AUTOSAR XML (schema 4-3-0)
package /DBCImport/CANTP
  can tp config CanTpConfig_Project: communication-cluster=Project, can-tp-ecu=ECU1
    4 x can tp channel, all with channel-mode=HALF-DUPLEX-MODE:
      CanTpChannel{0..3}: channel-id={0..3}
    tp-connections:
      addressing-format=STANDARD, can-tp-channel=CanTpChannel1, data-pdu=NPdu_Project_GST_Msg_TP2, flow-control-pdu=NPdu_Project_ECU1_Msg_TP2, max-block-size=0, padding-activation=true, ta-type=PHYSICAL, tp-sdu=ISignalIPdu_Project_GST_Msg_TP2
      addressing-format=STANDARD, can-tp-channel=CanTpChannel0, data-pdu=NPdu_Project_GST_Msg_TP1, flow-control-pdu=NPdu_Project_ECU1_Msg_TP1, max-block-size=0, padding-activation=true, ta-type=PHYSICAL, tp-sdu=ISignalIPdu_Project_GST_Msg_TP1
      addressing-format=STANDARD, can-tp-channel=CanTpChannel2, data-pdu=NPdu_Project_ECU1_GST_Msg_TP, flow-control-pdu=NPdu_Project_GST_Msg_TP_Phys, max-block-size=0, padding-activation=true, ta-type=PHYSICAL, tp-sdu=DcmIPdu_Project_ECU1_GST_Msg_TP
      addressing-format=STANDARD, can-tp-channel=CanTpChannel2, data-pdu=NPdu_Project_GST_Msg_TP_Phys, flow-control-pdu=NPdu_Project_ECU1_GST_Msg_TP, max-block-size=0, padding-activation=true, ta-type=PHYSICAL, tp-sdu=DcmIPdu_Project_GST_Msg_TP_Phys
      addressing-format=STANDARD, can-tp-channel=CanTpChannel1, data-pdu=NPdu_Project_ECU1_Msg_TP2, flow-control-pdu=NPdu_Project_GST_Msg_TP2, max-block-size=0, padding-activation=true, ta-type=PHYSICAL, tp-sdu=ISignalIPdu_Project_ECU1_Msg_TP2
      addressing-format=STANDARD, can-tp-channel=CanTpChannel3, data-pdu=NPdu_Project_GST_Msg_TP_Func, max-block-size=0, padding-activation=true, ta-type=FUNCTIONAL, tp-sdu=DcmIPdu_Project_GST_Msg_TP_Func
      addressing-format=STANDARD, can-tp-channel=CanTpChannel0, data-pdu=NPdu_Project_ECU1_Msg_TP1, flow-control-pdu=NPdu_Project_GST_Msg_TP1, max-block-size=0, padding-activation=true, ta-type=PHYSICAL, tp-sdu=ISignalIPdu_Project_ECU1_Msg_TP1
    can tp node ECU1: connector=Conn_ECU1_Project
package /DBCImport/SWCComposition
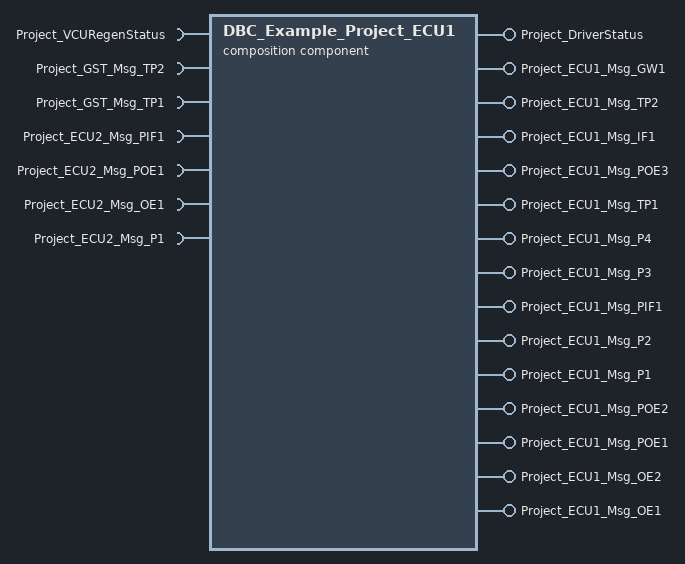
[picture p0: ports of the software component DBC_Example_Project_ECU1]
  composition sw component type DBC_Example_Project_ECU1
    15 x provide port:
      Project_DriverStatus: provided-interface=Project_DriverStatus
      Project_ECU1_Msg_GW1: provided-interface=Project_ECU1_Msg_GW1
      Project_ECU1_Msg_TP2: provided-interface=Project_ECU1_Msg_TP2
      Project_ECU1_Msg_IF1: provided-interface=Project_ECU1_Msg_IF1
      Project_ECU1_Msg_POE3: provided-interface=Project_ECU1_Msg_POE3
      Project_ECU1_Msg_TP1: provided-interface=Project_ECU1_Msg_TP1
      Project_ECU1_Msg_P4: provided-interface=Project_ECU1_Msg_P4
      Project_ECU1_Msg_P3: provided-interface=Project_ECU1_Msg_P3
      Project_ECU1_Msg_PIF1: provided-interface=Project_ECU1_Msg_PIF1
      Project_ECU1_Msg_P2: provided-interface=Project_ECU1_Msg_P2
      Project_ECU1_Msg_P1: provided-interface=Project_ECU1_Msg_P1
      Project_ECU1_Msg_POE2: provided-interface=Project_ECU1_Msg_POE2
      Project_ECU1_Msg_POE1: provided-interface=Project_ECU1_Msg_POE1
      Project_ECU1_Msg_OE2: provided-interface=Project_ECU1_Msg_OE2
      Project_ECU1_Msg_OE1: provided-interface=Project_ECU1_Msg_OE1
    7 x require port:
      Project_VCURegenStatus: required-interface=Project_VCURegenStatus
      Project_GST_Msg_TP2: required-interface=Project_GST_Msg_TP2
      Project_GST_Msg_TP1: required-interface=Project_GST_Msg_TP1
      Project_ECU2_Msg_PIF1: required-interface=Project_ECU2_Msg_PIF1
      Project_ECU2_Msg_POE1: required-interface=Project_ECU2_Msg_POE1
      Project_ECU2_Msg_OE1: required-interface=Project_ECU2_Msg_OE1
      Project_ECU2_Msg_P1: required-interface=Project_ECU2_Msg_P1
package /DBCImport/CLUSTERS
  can cluster Project: baudrate=500000, protocol-name=CAN, speed=500
    can physical channel Project: comm-connectors=Conn_ECU1_Project
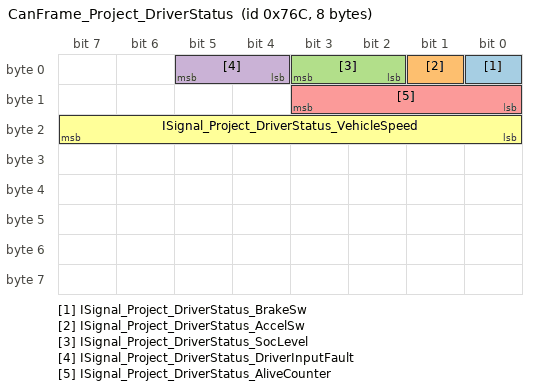
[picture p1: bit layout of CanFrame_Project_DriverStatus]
      frame CanFrame_Project_DriverStatus: id 0x76C, frame-length=8, can-addressing-mode=STANDARD, can-fd-frame-support=false
        pdu ISignalIPdu_Project_DriverStatus: length=8, minimum-delay=0.0, transmission-mode-true-timing=cyclic-timing={time-offset=0.0, time-period=0.01}
          signal ISignal_Project_DriverStatus_BrakeSw: start 0, 1 bit, little-endian, init-value=0, base-type=boolean, compu {0=OFF, 1=ON, phys=raw for raw 0..1}, transfer-property=PENDING
          signal ISignal_Project_DriverStatus_AccelSw: start 1, 1 bit, little-endian, init-value=0, base-type=boolean, compu {0=OFF, 1=ON, phys=raw for raw 0..1}, transfer-property=PENDING
          signal ISignal_Project_DriverStatus_SocLevel: start 2, 2 bit, little-endian, init-value=0, base-type=uint8, compu {0=LOW, 1=MID, 2=HIGH, 3=FULL, phys=raw for raw 0..3}, transfer-property=PENDING
          signal ISignal_Project_DriverStatus_DriverInputFault: start 4, 2 bit, little-endian, init-value=0, base-type=uint8, compu-method=ISignal_Project_DriverStatus_DriverInputFault, transfer-property=PENDING
          signal ISignal_Project_DriverStatus_AliveCounter: start 8, 4 bit, little-endian, init-value=0, base-type=uint8, compu {phys=raw for raw 0..15}, transfer-property=PENDING
          signal ISignal_Project_DriverStatus_VehicleSpeed: start 16, 8 bit, little-endian, init-value=0, base-type=uint8, compu {phys=raw for raw 0..255; unit km/h}, unit=km/h, transfer-property=PENDING
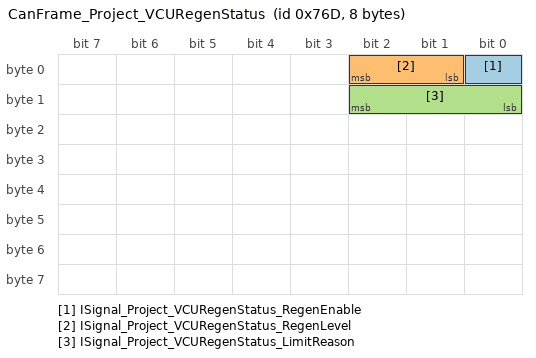
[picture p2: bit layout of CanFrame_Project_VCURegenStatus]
      frame CanFrame_Project_VCURegenStatus: id 0x76D, frame-length=8, can-addressing-mode=STANDARD, can-fd-frame-support=false
        pdu ISignalIPdu_Project_VCURegenStatus: length=8, minimum-delay=0.0, transmission-mode-true-timing=cyclic-timing={time-offset=0.0, time-period=0.01}
          signal ISignal_Project_VCURegenStatus_RegenEnable: start 0, 1 bit, little-endian, init-value=0, base-type=boolean, compu {0=DISABLE, 1=ENABLE, phys=raw for raw 0..1}, transfer-property=PENDING
          signal ISignal_Project_VCURegenStatus_RegenLevel: start 1, 2 bit, little-endian, init-value=0, base-type=uint8, compu {0=NONE, 1=LOW, 2=MID, 3=HIGH, phys=raw for raw 0..3}, transfer-property=PENDING
          signal ISignal_Project_VCURegenStatus_LimitReason: start 8, 3 bit, little-endian, init-value=0, base-type=uint8, compu-method=ISignal_Project_VCURegenStatus_LimitReason, transfer-property=PENDING
      frame CanFrame_Project_GST_Msg_TP2: id 0x707, frame-length=8, can-addressing-mode=STANDARD, can-fd-frame-support=false
        pdu ISignalIPdu_Project_GST_Msg_TP2: length=8, minimum-delay=0.0, transmission-mode-true-timing=event-controlled-timing={number-of-repetitions=0, repetition-period=0.0}
          signal ISignal_Project_GST_Msg_TP2_Project_GST_Msg_TP2_signal: start 0, 64 bit, opaque, init-value=8 x 0, compu {phys=raw for raw 0}, implementation-data-type=array8uint8, transfer-property=TRIGGERED-WITHOUT-REPETITION
        n pdu NPdu_Project_GST_Msg_TP2: length=8, meta-data-length=0
      frame CanFrame_Project_GST_Msg_TP1: id 0x706, frame-length=8, can-addressing-mode=STANDARD, can-fd-frame-support=false
        pdu ISignalIPdu_Project_GST_Msg_TP1: length=8, minimum-delay=0.0, transmission-mode-true-timing=event-controlled-timing={number-of-repetitions=0, repetition-period=0.0}
          signal ISignal_Project_GST_Msg_TP1_Project_GST_Msg_TP1_signal: start 0, 64 bit, opaque, init-value=8 x 0, compu {phys=raw for raw 0}, implementation-data-type=array8uint8, transfer-property=TRIGGERED-WITHOUT-REPETITION
        n pdu NPdu_Project_GST_Msg_TP1: length=8, meta-data-length=0
      frame CanFrame_Project_ECU1_GST_Msg_TP: id 0x705, frame-length=8, can-addressing-mode=STANDARD, can-fd-frame-support=false
        dcm i pdu DcmIPdu_Project_ECU1_GST_Msg_TP: length=8
        n pdu NPdu_Project_ECU1_GST_Msg_TP: length=8, meta-data-length=0
      frame CanFrame_Project_ECU1_Msg_GW1: id 0x55, frame-length=8, can-addressing-mode=STANDARD, can-fd-frame-support=false
        pdu ISignalIPdu_Project_ECU1_Msg_GW1: length=8, minimum-delay=0.02, transmission-mode-true-timing=event-controlled-timing={number-of-repetitions=3, repetition-period=0.04}
          signal ISignal_Project_ECU1_Msg_GW1_ECU1_Msg_GW1_Sig1: start 7, 8 bit, big-endian, init-value=0, base-type=uint8, compu {phys=raw for raw 0}, transfer-property=TRIGGERED
          signal ISignal_Project_ECU1_Msg_GW1_ECU1_Msg_GW1_Sig2: start 15, 8 bit, big-endian, init-value=0, base-type=uint8, compu {phys=raw for raw 0}, transfer-property=TRIGGERED
      frame CanFrame_Project_GST_Msg_TP_Phys: id 0x703, frame-length=8, can-addressing-mode=STANDARD, can-fd-frame-support=false
        dcm i pdu DcmIPdu_Project_GST_Msg_TP_Phys: length=8
        n pdu NPdu_Project_GST_Msg_TP_Phys: length=8, meta-data-length=0
      frame CanFrame_Project_ECU1_Msg_TP2: id 0x704, frame-length=8, can-addressing-mode=STANDARD, can-fd-frame-support=false
        pdu ISignalIPdu_Project_ECU1_Msg_TP2: length=8, minimum-delay=0.0, transmission-mode-true-timing=event-controlled-timing={number-of-repetitions=0, repetition-period=0.0}
          signal ISignal_Project_ECU1_Msg_TP2_Project_ECU1_Msg_TP2_signal: start 0, 64 bit, opaque, init-value=8 x 0, compu {phys=raw for raw 0}, implementation-data-type=array8uint8, transfer-property=TRIGGERED-WITHOUT-REPETITION
        n pdu NPdu_Project_ECU1_Msg_TP2: length=8, meta-data-length=0
      frame CanFrame_Project_ECU2_Msg_PIF1: id 0x301, frame-length=8, can-addressing-mode=STANDARD, can-fd-frame-support=false
        pdu ISignalIPdu_Project_ECU2_Msg_PIF1: length=8, minimum-delay=0.02, transmission-mode-true-timing={cyclic-timing={time-offset=0.0, time-period=0.5}, event-controlled-timing={number-of-repetitions=3, repetition-period=0.2}}
          signal ISignal_Project_ECU2_Msg_PIF1_ECU2_Msg_PIF1_Sig1: start 23, 8 bit, big-endian, init-value=0, base-type=uint8, compu {phys=raw for raw 0}, transfer-property=TRIGGERED
          signal ISignal_Project_ECU2_Msg_PIF1_ECU2_Msg_PIF1_Sig2: start 31, 8 bit, big-endian, init-value=0, base-type=uint8, compu {phys=raw for raw 0}, transfer-property=TRIGGERED
      frame CanFrame_Project_ECU2_Msg_POE1: id 0x103, frame-length=8, can-addressing-mode=STANDARD, can-fd-frame-support=false
        pdu ISignalIPdu_Project_ECU2_Msg_POE1: length=8, minimum-delay=0.02, transmission-mode-true-timing={cyclic-timing={time-offset=0.0, time-period=0.5}, event-controlled-timing={number-of-repetitions=3, repetition-period=0.04}}
          signal ISignal_Project_ECU2_Msg_POE1_ECU2_Msg_POE1_Sig2: start 23, 8 bit, big-endian, init-value=0, base-type=uint8, compu {phys=raw for raw 0}, transfer-property=TRIGGERED-ON-CHANGE
          signal ISignal_Project_ECU2_Msg_POE1_ECU2_Msg_POE1_Sig1: start 31, 8 bit, big-endian, init-value=0, base-type=uint8, compu {phys=raw for raw 0}, transfer-property=TRIGGERED
      frame CanFrame_Project_ECU1_Msg_IF1: id 0x200, frame-length=8, can-addressing-mode=STANDARD, can-fd-frame-support=false
        pdu ISignalIPdu_Project_ECU1_Msg_IF1: length=8, minimum-delay=0.02, transmission-mode-true-timing=event-controlled-timing={number-of-repetitions=3, repetition-period=0.2}
          signal ISignal_Project_ECU1_Msg_IF1_ECU1_Msg_IF1_Sig1: start 7, 8 bit, big-endian, init-value=0, base-type=uint8, compu {phys=raw for raw 0}, transfer-property=TRIGGERED
          signal ISignal_Project_ECU1_Msg_IF1_ECU1_Msg_IF1_Sig2: start 15, 8 bit, big-endian, init-value=0, base-type=uint8, compu {phys=raw for raw 0}, transfer-property=TRIGGERED
      frame CanFrame_Project_ECU2_Msg_OE1: id 0x3, frame-length=8, can-addressing-mode=STANDARD, can-fd-frame-support=false
        pdu ISignalIPdu_Project_ECU2_Msg_OE1: length=8, minimum-delay=0.02, transmission-mode-true-timing=event-controlled-timing={number-of-repetitions=3, repetition-period=0.04}
          signal ISignal_Project_ECU2_Msg_OE1_ECU2_Msg_OE1_Sig1: start 7, 8 bit, big-endian, init-value=0, base-type=uint8, compu {phys=raw for raw 0}, transfer-property=TRIGGERED-WITHOUT-REPETITION
          signal ISignal_Project_ECU2_Msg_OE1_ECU2_Msg_OE1_Sig2: start 15, 8 bit, big-endian, init-value=0, base-type=uint8, compu {phys=raw for raw 0}, transfer-property=TRIGGERED-WITHOUT-REPETITION
      frame CanFrame_Project_ECU2_Msg_P1: id 0x503, frame-length=2, can-addressing-mode=STANDARD, can-fd-frame-support=false
        pdu ISignalIPdu_Project_ECU2_Msg_P1: length=2, minimum-delay=0.02, transmission-mode-true-timing=cyclic-timing={time-offset=0.0, time-period=0.5}
          signal ISignal_Project_ECU2_Msg_P1_ECU2_Msg_P1_Sig1: start 7, 8 bit, big-endian, init-value=0, base-type=uint8, compu {phys=raw for raw 0}, transfer-property=PENDING
          signal ISignal_Project_ECU2_Msg_P1_ECU2_Msg_P1_Sig2: start 15, 8 bit, big-endian, init-value=0, base-type=uint8, compu {phys=raw for raw 0}, transfer-property=PENDING
      frame CanFrame_Project_ECU1_Msg_POE3: id 0x100, frame-length=8, can-addressing-mode=STANDARD, can-fd-frame-support=false
        pdu ISignalIPdu_Project_ECU1_Msg_POE3: length=8, minimum-delay=0.02, transmission-mode-true-timing={cyclic-timing={time-offset=0.0, time-period=0.2}, event-controlled-timing={number-of-repetitions=3, repetition-period=0.04}}
          signal ISignal_Project_ECU1_Msg_POE3_ECU1_Msg_POE3_Sig1: start 7, 8 bit, big-endian, init-value=0, base-type=uint8, compu {phys=raw for raw 0..255}, transfer-property=TRIGGERED-WITHOUT-REPETITION
          signal ISignal_Project_ECU1_Msg_POE3_ECU1_Msg_POE3_Sig2: start 15, 8 bit, big-endian, init-value=0, base-type=uint8, compu {phys=raw for raw 0}, transfer-property=TRIGGERED-ON-CHANGE-WITHOUT-REPETITION
      frame CanFrame_Project_GST_Msg_TP_Func: id 0x7DF, frame-length=8, can-addressing-mode=STANDARD, can-fd-frame-support=false
        dcm i pdu DcmIPdu_Project_GST_Msg_TP_Func: length=8
        n pdu NPdu_Project_GST_Msg_TP_Func: length=8, meta-data-length=0
      frame CanFrame_Project_ECU1_Msg_TP1: id 0x701, frame-length=8, can-addressing-mode=STANDARD, can-fd-frame-support=false
        pdu ISignalIPdu_Project_ECU1_Msg_TP1: length=8, minimum-delay=0.0, transmission-mode-true-timing=event-controlled-timing={number-of-repetitions=0, repetition-period=0.0}
          signal ISignal_Project_ECU1_Msg_TP1_Project_ECU1_Msg_TP1_signal: start 0, 64 bit, opaque, init-value=8 x 0, compu {phys=raw for raw 0}, implementation-data-type=array8uint8, transfer-property=TRIGGERED-WITHOUT-REPETITION
        n pdu NPdu_Project_ECU1_Msg_TP1: length=8, meta-data-length=0
      frame CanFrame_Project_ECU1_Msg_P4: id 0x602, frame-length=8, can-addressing-mode=STANDARD, can-fd-frame-support=false
        pdu ISignalIPdu_Project_ECU1_Msg_P4: length=8, minimum-delay=0.02, transmission-mode-true-timing=cyclic-timing={time-offset=0.0, time-period=0.2}
          signal ISignal_Project_ECU1_Msg_P4_ECU1_Msg_P4_Sig1: start 7, 8 bit, big-endian, init-value=0, base-type=uint8, compu {phys=raw for raw 0}, transfer-property=PENDING
          signal ISignal_Project_ECU1_Msg_P4_ECU1_Msg_P4_Sig2: start 15, 8 bit, big-endian, init-value=0, base-type=uint8, compu {phys=raw for raw 0}, transfer-property=PENDING
      frame CanFrame_Project_ECU1_Msg_P3: id 0x601, frame-length=8, can-addressing-mode=STANDARD, can-fd-frame-support=false
        pdu ISignalIPdu_Project_ECU1_Msg_P3: length=8, minimum-delay=0.02, transmission-mode-true-timing=cyclic-timing={time-offset=0.0, time-period=0.2}
          signal ISignal_Project_ECU1_Msg_P3_ECU1_Msg_P3_Sig1: start 7, 8 bit, big-endian, init-value=0, base-type=uint8, compu {phys=raw for raw 0}, transfer-property=PENDING
          signal ISignal_Project_ECU1_Msg_P3_ECU1_Msg_P3_Sig2: start 15, 8 bit, big-endian, init-value=0, base-type=uint8, compu {phys=raw for raw 0}, transfer-property=PENDING
      frame CanFrame_Project_ECU1_Msg_PIF1: id 0x300, frame-length=8, can-addressing-mode=STANDARD, can-fd-frame-support=false
        pdu ISignalIPdu_Project_ECU1_Msg_PIF1: length=8, minimum-delay=0.02, transmission-mode-true-timing={cyclic-timing={time-offset=0.0, time-period=0.5}, event-controlled-timing={number-of-repetitions=3, repetition-period=0.2}}
          signal ISignal_Project_ECU1_Msg_PIF1_ECU1_Msg_PIF1_Sig1: start 7, 8 bit, big-endian, init-value=0, base-type=uint8, compu {phys=raw for raw 0}, transfer-property=TRIGGERED
          signal ISignal_Project_ECU1_Msg_PIF1_ECU1_Msg_PIF1_Sig2: start 15, 8 bit, big-endian, init-value=0, base-type=uint8, compu {phys=raw for raw 0}, transfer-property=TRIGGERED
      frame CanFrame_Project_ECU1_Msg_P2: id 0x502, frame-length=8, can-addressing-mode=STANDARD, can-fd-frame-support=false
        pdu ISignalIPdu_Project_ECU1_Msg_P2: length=8, minimum-delay=0.02, transmission-mode-true-timing=cyclic-timing={time-offset=0.0, time-period=0.2}
          signal ISignal_Project_ECU1_Msg_P2_ECU1_Msg_P2_Sig1: start 7, 8 bit, big-endian, init-value=0, base-type=uint8, compu {phys=raw for raw 0}, transfer-property=PENDING
          signal ISignal_Project_ECU1_Msg_P2_ECU1_Msg_P2_Sig2: start 15, 8 bit, big-endian, init-value=0, base-type=uint8, compu {phys=raw for raw 0}, transfer-property=PENDING
      frame CanFrame_Project_ECU1_Msg_P1: id 0x501, frame-length=8, can-addressing-mode=STANDARD, can-fd-frame-support=false
        pdu ISignalIPdu_Project_ECU1_Msg_P1: length=8, minimum-delay=0.02, transmission-mode-true-timing=cyclic-timing={time-offset=0.0, time-period=0.5}
          signal ISignal_Project_ECU1_Msg_P1_ECU1_Msg_P1_Sig1: start 7, 8 bit, big-endian, init-value=0, base-type=uint8, compu {phys=raw for raw 0}, transfer-property=PENDING
          signal ISignal_Project_ECU1_Msg_P1_ECU1_Msg_P1_Sig2: start 15, 8 bit, big-endian, init-value=0, base-type=uint8, compu {phys=raw for raw 0}, transfer-property=PENDING
      frame CanFrame_Project_ECU1_Msg_POE2: id 0x102, frame-length=8, can-addressing-mode=STANDARD, can-fd-frame-support=false
        pdu ISignalIPdu_Project_ECU1_Msg_POE2: length=8, minimum-delay=0.02, transmission-mode-true-timing={cyclic-timing={time-offset=0.0, time-period=0.2}, event-controlled-timing={number-of-repetitions=3, repetition-period=0.04}}
          signal ISignal_Project_ECU1_Msg_POE2_ECU1_Msg_POE2_Sig1: start 7, 8 bit, big-endian, init-value=0, base-type=uint8, compu {phys=raw for raw 0}, transfer-property=TRIGGERED
          signal ISignal_Project_ECU1_Msg_POE2_ECU1_Msg_POE2_Sig2: start 15, 8 bit, big-endian, init-value=0, base-type=uint8, compu {phys=raw for raw 0}, transfer-property=TRIGGERED-ON-CHANGE
      frame CanFrame_Project_ECU1_Msg_POE1: id 0x101, frame-length=8, can-addressing-mode=STANDARD, can-fd-frame-support=false
        pdu ISignalIPdu_Project_ECU1_Msg_POE1: length=8, minimum-delay=0.02, transmission-mode-true-timing={cyclic-timing={time-offset=0.0, time-period=0.2}, event-controlled-timing={number-of-repetitions=3, repetition-period=0.04}}
          signal ISignal_Project_ECU1_Msg_POE1_ECU1_Msg_POE1_Sig1: start 7, 8 bit, big-endian, init-value=0, base-type=uint8, compu {phys=raw for raw 0}, transfer-property=TRIGGERED-WITHOUT-REPETITION
          signal ISignal_Project_ECU1_Msg_POE1_ECU1_Msg_POE1_Sig2: start 15, 8 bit, big-endian, init-value=0, base-type=uint8, compu {phys=raw for raw 0}, transfer-property=TRIGGERED-ON-CHANGE-WITHOUT-REPETITION
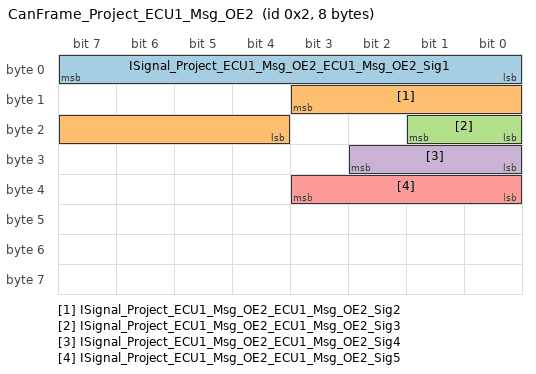
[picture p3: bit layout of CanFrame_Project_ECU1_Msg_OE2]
      frame CanFrame_Project_ECU1_Msg_OE2: id 0x2, frame-length=8, can-addressing-mode=STANDARD, can-fd-frame-support=false
        pdu ISignalIPdu_Project_ECU1_Msg_OE2: length=8, minimum-delay=0.02, transmission-mode-true-timing=event-controlled-timing={number-of-repetitions=3, repetition-period=0.04}
          signal ISignal_Project_ECU1_Msg_OE2_ECU1_Msg_OE2_Sig1: start 7, 8 bit, big-endian, init-value=0, base-type=uint8, compu {phys=raw for raw 0}, transfer-property=TRIGGERED
          signal ISignal_Project_ECU1_Msg_OE2_ECU1_Msg_OE2_Sig2: start 11, 8 bit, big-endian, init-value=0, base-type=uint8, compu {phys=raw for raw 0}, transfer-property=TRIGGERED-ON-CHANGE
          signal ISignal_Project_ECU1_Msg_OE2_ECU1_Msg_OE2_Sig3: start 17, 2 bit, big-endian, init-value=0, base-type=uint8, compu {phys=raw for raw 0..3}, transfer-property=TRIGGERED-ON-CHANGE
          signal ISignal_Project_ECU1_Msg_OE2_ECU1_Msg_OE2_Sig4: start 26, 3 bit, big-endian, init-value=0, base-type=uint8, compu {phys=raw for raw 0..7}, transfer-property=TRIGGERED-ON-CHANGE
          signal ISignal_Project_ECU1_Msg_OE2_ECU1_Msg_OE2_Sig5: start 35, 4 bit, big-endian, init-value=0, base-type=uint8, compu {phys=raw for raw 0..15}, transfer-property=TRIGGERED-ON-CHANGE
      frame CanFrame_Project_ECU1_Msg_OE1: id 0x1, frame-length=8, can-addressing-mode=STANDARD, can-fd-frame-support=false
        pdu ISignalIPdu_Project_ECU1_Msg_OE1: length=8, minimum-delay=0.02, transmission-mode-true-timing=event-controlled-timing={number-of-repetitions=3, repetition-period=0.04}
          signal ISignal_Project_ECU1_Msg_OE1_ECU1_Msg_OE1_Sig1: start 7, 8 bit, big-endian, init-value=0, base-type=uint8, compu {phys=raw for raw 0}, transfer-property=TRIGGERED-WITHOUT-REPETITION
          signal ISignal_Project_ECU1_Msg_OE1_ECU1_Msg_OE1_Sig2: start 12, 8 bit, little-endian, init-value=0, base-type=uint8, compu {phys=raw for raw 0}, transfer-property=TRIGGERED-ON-CHANGE-WITHOUT-REPETITION
package /DBCImport/COMPUMETHODS
  compu method ISignal_Project_DriverStatus_DriverInputFault: 0=NONE, 1=PEDAL_CONFLICT, 2=INPUT_READ_FAIL, 3=RESERVED, phys=raw for raw 0..3
  compu method ISignal_Project_VCURegenStatus_LimitReason: 0=NONE, 1=LOW_SPEED, 2=SOC_FULL, 3=FAULT, 4=TIMEOUT, phys=raw for raw 0..7
package /DBCImport/IPDUGROUPS
  i signal i pdu group ISignalIPduGroupRx_ECU1_Project: communication-direction=IN, communication-mode=rx
    i-signal-i-pdus:
      ISignalIPdu_Project_VCURegenStatus
      ISignalIPdu_Project_GST_Msg_TP2
      ISignalIPdu_Project_GST_Msg_TP1
      ISignalIPdu_Project_ECU2_Msg_PIF1
      ISignalIPdu_Project_ECU2_Msg_POE1
      ISignalIPdu_Project_ECU2_Msg_OE1
      ISignalIPdu_Project_ECU2_Msg_P1
  i signal i pdu group ISignalIPduGroupTx_ECU1_Project: communication-direction=OUT, communication-mode=tx
    i-signal-i-pdus:
      ISignalIPdu_Project_DriverStatus
      ISignalIPdu_Project_ECU1_Msg_GW1
      ISignalIPdu_Project_ECU1_Msg_TP2
      ISignalIPdu_Project_ECU1_Msg_IF1
      ISignalIPdu_Project_ECU1_Msg_POE3
      ISignalIPdu_Project_ECU1_Msg_TP1
      ISignalIPdu_Project_ECU1_Msg_P4
      ISignalIPdu_Project_ECU1_Msg_P3
      ISignalIPdu_Project_ECU1_Msg_PIF1
      ISignalIPdu_Project_ECU1_Msg_P2
      ISignalIPdu_Project_ECU1_Msg_P1
      ISignalIPdu_Project_ECU1_Msg_POE2
      ISignalIPdu_Project_ECU1_Msg_POE1
      ISignalIPdu_Project_ECU1_Msg_OE2
      ISignalIPdu_Project_ECU1_Msg_OE1
package /DBCImport/INTERFACES
  22 x sender receiver interface:
    Project_DriverStatus
      6 x data, all with init-value=0:
        BrakeSw: base-type=boolean, compu {0=OFF, 1=ON, phys=raw for raw 0..1}, type=boolean
        AccelSw: base-type=boolean, compu {0=OFF, 1=ON, phys=raw for raw 0..1}, type=boolean
        SocLevel: base-type=uint8, compu {0=LOW, 1=MID, 2=HIGH, 3=FULL, phys=raw for raw 0..3}, type=uint8
        DriverInputFault: base-type=uint8, compu-method=ISignal_Project_DriverStatus_DriverInputFault, type=uint8
        AliveCounter: base-type=uint8, compu {phys=raw for raw 0..15}, type=uint8
        VehicleSpeed: base-type=uint8, compu {phys=raw for raw 0..255; unit km/h}, unit=km/h, type=uint8
    Project_ECU1_Msg_GW1
      data ECU1_Msg_GW1_Sig2: base-type=uint8, compu {phys=raw for raw 0}, type=uint8, init-value=0
      data ECU1_Msg_GW1_Sig1: base-type=uint8, compu {phys=raw for raw 0}, type=uint8, init-value=0
    Project_ECU1_Msg_IF1
      data ECU1_Msg_IF1_Sig2: base-type=uint8, compu {phys=raw for raw 0}, type=uint8, init-value=0
      data ECU1_Msg_IF1_Sig1: base-type=uint8, compu {phys=raw for raw 0}, type=uint8, init-value=0
    Project_ECU1_Msg_OE1
      data ECU1_Msg_OE1_Sig2: base-type=uint8, compu {phys=raw for raw 0}, type=uint8, init-value=0
      data ECU1_Msg_OE1_Sig1: base-type=uint8, compu {phys=raw for raw 0}, type=uint8, init-value=0
    Project_ECU1_Msg_OE2
      5 x data, all with base-type=uint8, type=uint8, init-value=0:
        ECU1_Msg_OE2_Sig5: compu {phys=raw for raw 0..15}
        ECU1_Msg_OE2_Sig4: compu {phys=raw for raw 0..7}
        ECU1_Msg_OE2_Sig3: compu {phys=raw for raw 0..3}
        ECU1_Msg_OE2_Sig2: compu {phys=raw for raw 0}
        ECU1_Msg_OE2_Sig1: compu {phys=raw for raw 0}
    Project_ECU1_Msg_P1
      data ECU1_Msg_P1_Sig2: base-type=uint8, compu {phys=raw for raw 0}, type=uint8, init-value=0
      data ECU1_Msg_P1_Sig1: base-type=uint8, compu {phys=raw for raw 0}, type=uint8, init-value=0
    Project_ECU1_Msg_P2
      data ECU1_Msg_P2_Sig2: base-type=uint8, compu {phys=raw for raw 0}, type=uint8, init-value=0
      data ECU1_Msg_P2_Sig1: base-type=uint8, compu {phys=raw for raw 0}, type=uint8, init-value=0
    Project_ECU1_Msg_P3
      data ECU1_Msg_P3_Sig2: base-type=uint8, compu {phys=raw for raw 0}, type=uint8, init-value=0
      data ECU1_Msg_P3_Sig1: base-type=uint8, compu {phys=raw for raw 0}, type=uint8, init-value=0
    Project_ECU1_Msg_P4
      data ECU1_Msg_P4_Sig2: base-type=uint8, compu {phys=raw for raw 0}, type=uint8, init-value=0
      data ECU1_Msg_P4_Sig1: base-type=uint8, compu {phys=raw for raw 0}, type=uint8, init-value=0
    Project_ECU1_Msg_PIF1
      data ECU1_Msg_PIF1_Sig2: base-type=uint8, compu {phys=raw for raw 0}, type=uint8, init-value=0
      data ECU1_Msg_PIF1_Sig1: base-type=uint8, compu {phys=raw for raw 0}, type=uint8, init-value=0
    Project_ECU1_Msg_POE1
      data ECU1_Msg_POE1_Sig2: base-type=uint8, compu {phys=raw for raw 0}, type=uint8, init-value=0
      data ECU1_Msg_POE1_Sig1: base-type=uint8, compu {phys=raw for raw 0}, type=uint8, init-value=0
    Project_ECU1_Msg_POE2
      data ECU1_Msg_POE2_Sig2: base-type=uint8, compu {phys=raw for raw 0}, type=uint8, init-value=0
      data ECU1_Msg_POE2_Sig1: base-type=uint8, compu {phys=raw for raw 0}, type=uint8, init-value=0
    Project_ECU1_Msg_POE3
      data ECU1_Msg_POE3_Sig2: base-type=uint8, compu {phys=raw for raw 0}, type=uint8, init-value=0
      data ECU1_Msg_POE3_Sig1: base-type=uint8, compu {phys=raw for raw 0..255}, type=uint8, init-value=0
    Project_ECU1_Msg_TP1
      data Project_ECU1_Msg_TP1_signal: compu {phys=raw for raw 0}, sw-impl-policy=QUEUED, type=array8uint8
    Project_ECU1_Msg_TP2
      data Project_ECU1_Msg_TP2_signal: compu {phys=raw for raw 0}, sw-impl-policy=QUEUED, type=array8uint8
    Project_ECU2_Msg_OE1
      data ECU2_Msg_OE1_Sig2: base-type=uint8, compu {phys=raw for raw 0}, type=uint8, init-value=0
      data ECU2_Msg_OE1_Sig1: base-type=uint8, compu {phys=raw for raw 0}, type=uint8, init-value=0
    Project_ECU2_Msg_P1
      data ECU2_Msg_P1_Sig2: base-type=uint8, compu {phys=raw for raw 0}, type=uint8, init-value=0
      data ECU2_Msg_P1_Sig1: base-type=uint8, compu {phys=raw for raw 0}, type=uint8, init-value=0
    Project_ECU2_Msg_PIF1
      data ECU2_Msg_PIF1_Sig2: base-type=uint8, compu {phys=raw for raw 0}, type=uint8, init-value=0
      data ECU2_Msg_PIF1_Sig1: base-type=uint8, compu {phys=raw for raw 0}, type=uint8, init-value=0
    Project_ECU2_Msg_POE1
      data ECU2_Msg_POE1_Sig1: base-type=uint8, compu {phys=raw for raw 0}, type=uint8, init-value=0
      data ECU2_Msg_POE1_Sig2: base-type=uint8, compu {phys=raw for raw 0}, type=uint8, init-value=0
    Project_GST_Msg_TP1
      data Project_GST_Msg_TP1_signal: compu {phys=raw for raw 0}, sw-impl-policy=QUEUED, type=array8uint8
    Project_GST_Msg_TP2
      data Project_GST_Msg_TP2_signal: compu {phys=raw for raw 0}, sw-impl-policy=QUEUED, type=array8uint8
    Project_VCURegenStatus
      data RegenEnable: base-type=boolean, compu {0=DISABLE, 1=ENABLE, phys=raw for raw 0..1}, type=boolean, init-value=0
      data RegenLevel: base-type=uint8, compu {0=NONE, 1=LOW, 2=MID, 3=HIGH, phys=raw for raw 0..3}, type=uint8, init-value=0
      data LimitReason: base-type=uint8, compu-method=ISignal_Project_VCURegenStatus_LimitReason, type=uint8, init-value=0
package /DBCImport/UNITS_Project
  unit Unit_km_per_h: display-name=km/h
package /DBCImport/ImplementationDataTypes_Project
  impl type array8uint8: category=ARRAY
    element uint8: array-size=8, array-size-semantics=FIXED-SIZE, implementation-data-type=uint8
